# GD32E53x register map
File version: 1.0
CPU: CM33 r0p4, little endian, MPU, FPU, 4 interrupt priority bits
Registers are 32-bit, read-write, reset 0x0 unless marked. A register's access mark holds for its fields unless they carry their own. Offsets are from the block's base; [hi:lo] are bit positions; {n}, {i} and the like mark numbered series; 'fields as' and 'values as' point back to an identical list.

## EXMC — External memory controller
Base 0xA0000000
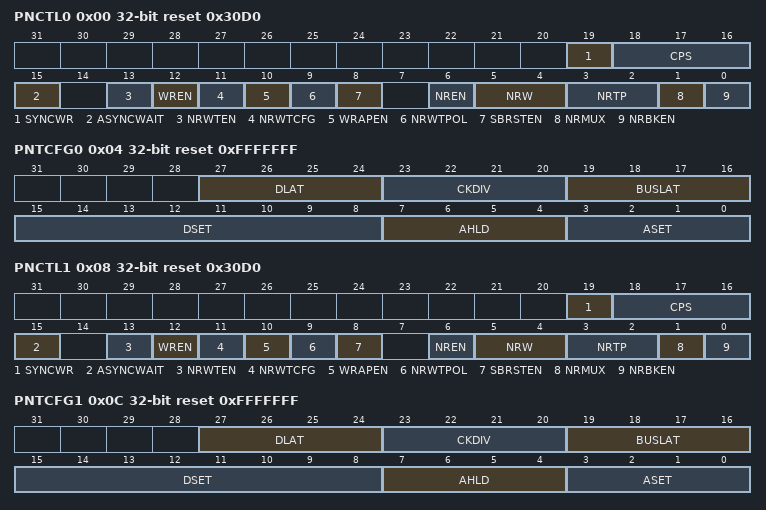
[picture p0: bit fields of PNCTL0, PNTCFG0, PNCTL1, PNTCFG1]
0x00 PNCTL0 reset 0x30D0 — PSRAM/NOR Flash control register 0
  [19] SYNCWR — Synchronous write
  [18:16] CPS — CRAM page size
  [15] ASYNCWAIT — Asynchronous wait
  [13] NRWTEN — NWAIT signal enable
  [12] WREN — Write enable
  [11] NRWTCFG — NWAIT signal configuration, only work in synchronous mode
  [10] WRAPEN — Wrapped burst mode enable
  [9] NRWTPOL — NWAIT signal polarity
  [8] SBRSTEN — Synchronous burst enable
  [6] NREN — NOR Flash access enable
  [5:4] NRW — NOR region memory data bus width
  [3:2] NRTP — NOR region memory type
  [1] NRMUX — NOR region memory address/data multiplexing
  [0] NRBKEN — NOR region enable
0x04 PNTCFG0 reset 0xFFFFFFF — PSRAM/NOR Flash timing configuration register 0
  [27:24] DLAT — Data latency for NOR Flash. Only valid in synchronous access
  [23:20] CKDIV — Synchronous clock divide ratio. This filed is only effect in synchronous mode.
  [19:16] BUSLAT — Bus latency
  [15:8] DSET — Data setup time
  [7:4] AHLD — Address hold time
  [3:0] ASET — Address setup time
0x08 PNCTL1 reset 0x30D0 — PSRAM/NOR Flash control register 1
  fields as PNCTL0
0x0C PNTCFG1 reset 0xFFFFFFF — PSRAM/NOR Flash timing configuration register 1
  fields as PNTCFG0
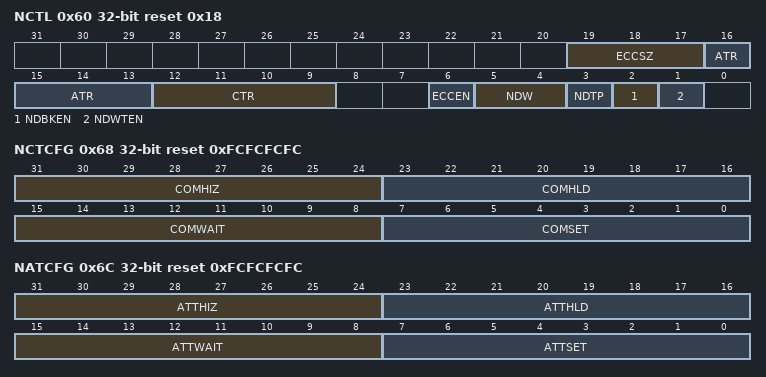
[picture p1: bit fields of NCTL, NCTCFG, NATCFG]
0x60 NCTL reset 0x18 — NAND Flash control registers
  [19:17] ECCSZ — ECC size
  [16:13] ATR — ALE to RE delay
  [12:9] CTR — CLE to RE delay
  [6] ECCEN — ECC enable
  [5:4] NDW — NAND bank memory data bus width
  [3] NDTP — NAND bank memory type
  [2] NDBKEN — NAND bank enable
  [1] NDWTEN — Wait function enable
0x64 NSTAT ro reset 0x42 — NAND Flash state registers
  [6] FFEPT — FIFO empty flag
0x68 NCTCFG reset 0xFCFCFCFC — NAND Flash common space timing configuration registers
  [31:24] COMHIZ — Common memory data bus HiZ time
  [23:16] COMHLD — Common memory hold time
  [15:8] COMWAIT — Common memory wait time
  [7:0] COMSET — Common memory setup time
0x6C NATCFG reset 0xFCFCFCFC — NAND Flash attribute space timing configuration registers
  [31:24] ATTHIZ — Attribute memory data bus HiZ time
  [23:16] ATTHLD — Attribute memory hold time
  [15:8] ATTWAIT — Attribute memory wait time
  [7:0] ATTSET — Attribute memory setup time
0x74 NECC ro — NAND Flash ECC registers
  [31:0] ECC — ECC result

## EXTI — External interrupt/event controller
Base 0x40010400
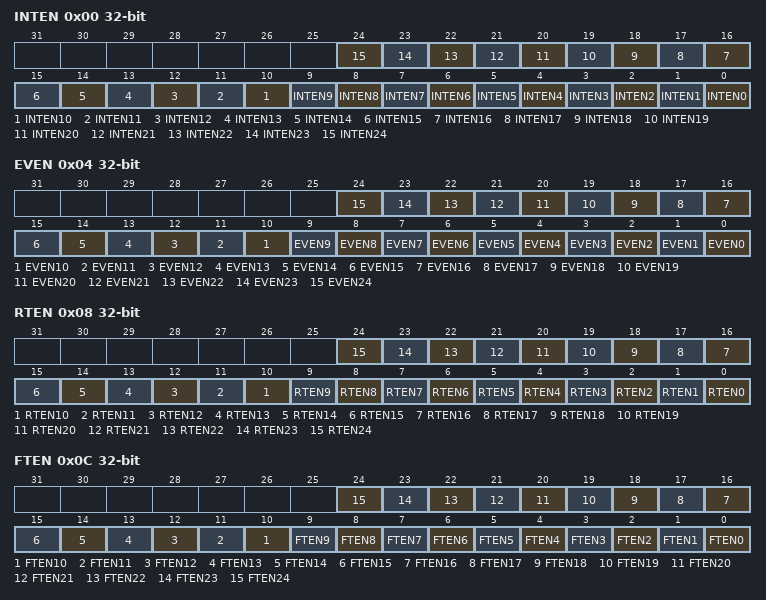
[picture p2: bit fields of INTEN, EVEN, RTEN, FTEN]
0x00 INTEN — Interrupt enable register (EXTI_INTEN)
  [n] INTEN{n} (n=0..24) — Enable Interrupt on line {n}
0x04 EVEN — Event enable register (EXTI_EVEN)
  [n] EVEN{n} (n=0..24) — Enable Event on line {n}
0x08 RTEN — Rising Edge Trigger Enable register (EXTI_RTEN)
  [n] RTEN{n} (n=0..24) — Rising edge trigger enable of line {n}
0x0C FTEN — Falling Egde Trigger Enable register (EXTI_FTEN)
  [n] FTEN{n} (n=0..24) — Falling edge trigger enable of line {n}
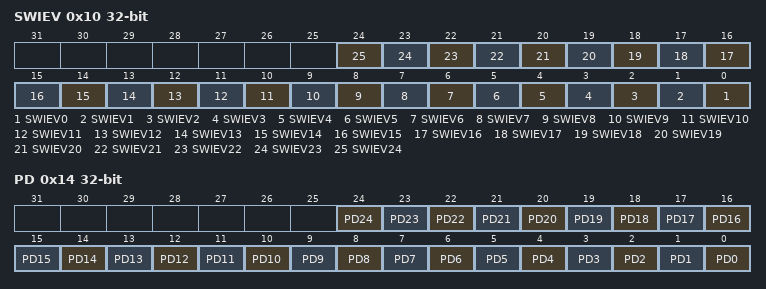
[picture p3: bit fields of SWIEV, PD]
0x10 SWIEV — Software interrupt event register (EXTI_SWIEV)
  [n] SWIEV{n} (n=0..24) — Interrupt/Event software trigger on line {n}
0x14 PD — Pending register (EXTI_PD)
  [n] PD{n} (n=0..24) — Interrupt pending status of line {n}

## FWDGT — free watchdog timer
Base 0x40003000
0x00 CTL wo — Control register
  [15:0] CMD — Key value
0x04 PSC — Prescaler register
  [3:0] PSC — Free watchdog timer prescaler selection
0x08 RLD reset 0xFFF — Reload register
  [11:0] RLD — Free watchdog timer counter reload value
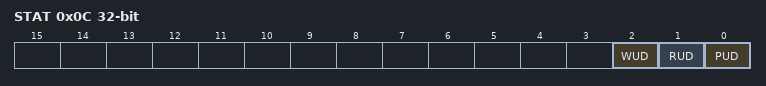
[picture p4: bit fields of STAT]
0x0C STAT ro — Status register
  [2] WUD — Watchdog counter window value update
  [1] RUD — Free watchdog timer counter reload value update
  [0] PUD — Free watchdog timer prescaler value update
0x10 WND reset 0xFFF — Window register
  [11:0] WND — Watchdog counter window value.

## GPIOA — General-purpose I/Os
Base 0x40010800
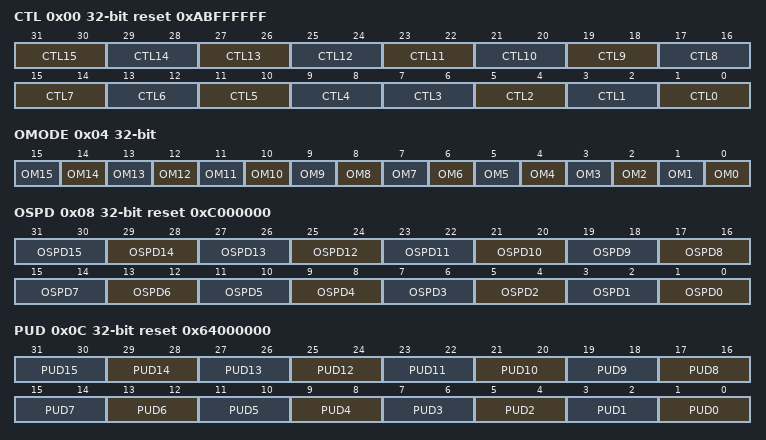
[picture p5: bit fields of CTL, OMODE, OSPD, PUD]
0x00 CTL reset 0xABFFFFFF — GPIO port control register
  [2n+1:2n] CTL{n} (n=7..15) — Port x configuration bits (x ={n})
  [13:12] CTL6 — Port x configuration bits (x =6 )
  [11:10] CTL5 — Port x configuration bits (x =5)
  [9:8] CTL4 — Port x configuration bits (x =4 )
  [2n+1:2n] CTL{n} (n=0..3) — Port x configuration bits (x ={n})
0x04 OMODE — GPIO port output mode register
  [n] OM{n} (n=0..15) — Port {n} output mode bit
0x08 OSPD reset 0xC000000 — GPIO port output speed register
  [2n+1:2n] OSPD{n} (n=0..15) — Port {n} output max speed bits
0x0C PUD reset 0x64000000 — GPIO port pull-up/pull-down register
  [2n+1:2n] PUD{n} (n=0..15) — Port {n} pull-up or pull-down bits
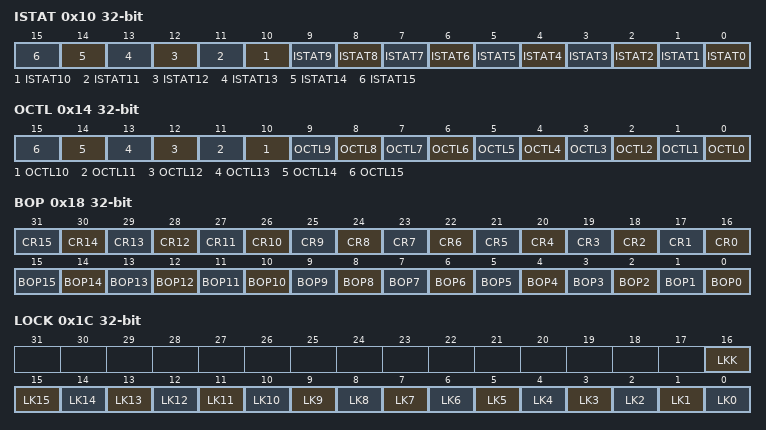
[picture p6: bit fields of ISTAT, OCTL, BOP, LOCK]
0x10 ISTAT ro — GPIO port input status register
  [n] ISTAT{n} (n=0..15) — Port input status (y ={n})
0x14 OCTL — GPIO port output control register
  [n] OCTL{n} (n=4..15) — Port output control (y ={n})
  [n] OCTL{n} (n=0..3) — Port output control (y = {n})
0x18 BOP wo — GPIO port bit operate register
  [n+16] CR{n} (n=0..15) — Port Clear bit {n}
  [n] BOP{n} (n=0..15) — Port Set bit {n}
0x1C LOCK — GPIO port configuration lock register
  [16] LKK — Lock sequence key
  [n] LK{n} (n=0..15) — Port Lock bit {n}
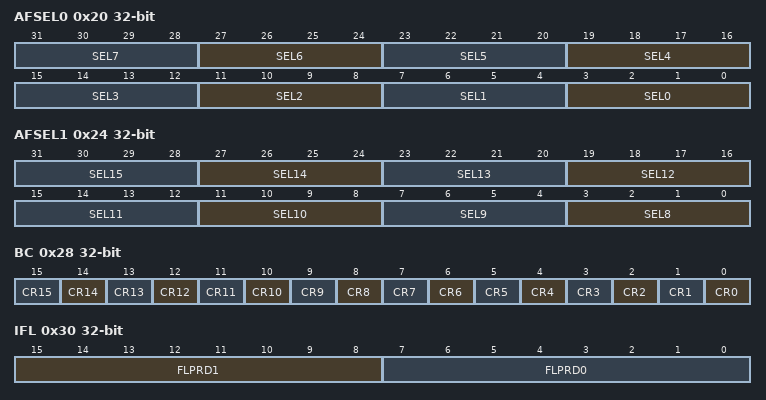
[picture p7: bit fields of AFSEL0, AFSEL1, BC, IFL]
0x20 AFSEL0 — GPIO alternate function selected register 0
  [4n+3:4n] SEL{n} (n=0..7) — Port {n} alternate function selected
0x24 AFSEL1 — GPIO alternate function selected register 1
  [4n-29:4n-32] SEL{n} (n=8..15) — Port {n} alternate function selected
0x28 BC wo — Bit clear register
  [n] CR{n} (n=0..15) — Port cleat bit
0x30 IFL — Input filtering register
  [15:8] FLPRD1 — Filter sampling period for GPIO8 to GPIO15:
  [7:0] FLPRD0 — Filter sampling period for GPIO1 to GPIO7:
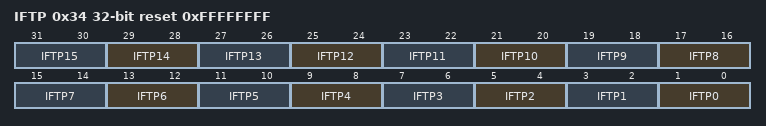
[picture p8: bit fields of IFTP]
0x34 IFTP reset 0xFFFFFFFF — Input filtering type register
  [2n+1:2n] IFTP{n} (n=0..15) — Pin {n} input filtering type bits

## GPIOB — General-purpose I/Os
Base 0x40010C00
Registers as GPIOA; these are added or differ:
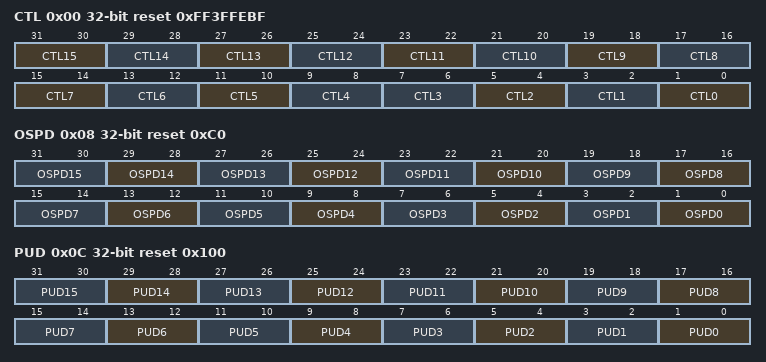
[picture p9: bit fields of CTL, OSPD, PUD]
0x00 CTL reset 0xFF3FFEBF — GPIO port control register
  fields as GPIOA.CTL
0x08 OSPD reset 0xC0 — GPIO port output speed register
  [2n+1:2n] OSPD{n} (n=0..15) — Port {n} output max speed bits
0x0C PUD reset 0x100 — GPIO port pull-up/pull-down register
  [2n+1:2n] PUD{n} (n=0..15) — Port {n} pull-up or pull-down bits

## GPIOC — General-purpose I/Os
Base 0x40011000
Same registers: GPIOD 0x40011400, GPIOE 0x40011800
Registers as GPIOA; these are added or differ:
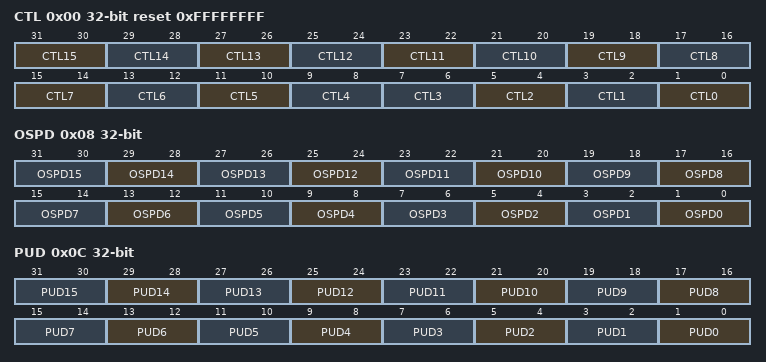
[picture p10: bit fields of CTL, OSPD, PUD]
0x00 CTL reset 0xFFFFFFFF — GPIO port control register
  fields as GPIOA.CTL
0x08 OSPD — GPIO port output speed register
  [2n+1:2n] OSPD{n} (n=0..15) — Port {n} output max speed bits
0x0C PUD — GPIO port pull-up/pull-down register
  [2n+1:2n] PUD{n} (n=0..15) — Port {n} pull-up or pull-down bits
